# ATtiny26 device description
Architecture: AVR8; Family: tinyAVR
Registers are 8-bit, access not given, no defined reset value unless marked. A register's access mark holds for its fields unless they carry their own. Offsets are from the block's base; [hi:lo] are bit positions; 'fields as' and 'values as' point back to an identical list.

## PORTA — I/O Port
Instances: PORTA 0x00
0x39 PINA — Port A Input Pins
0x3A DDRA — Port A Data Direction Register
0x3B PORTA — Port A Data Register

## PORTB — I/O Port
Instances: PORTB 0x00
0x36 PINB — Port B Input Pins
0x37 DDRB — Port B Data Direction Register
0x38 PORTB — Port B Data Register

## EEPROM
Instances: EEPROM 0x00
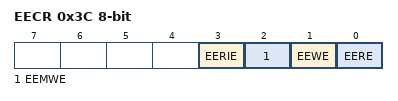
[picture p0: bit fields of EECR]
0x3C EECR — EEPROM Control Register
  [3] EERIE — EEProm Ready Interrupt Enable
  [2] EEMWE — EEPROM Master Write Enable
  [1] EEWE — EEPROM Write Enable
  [0] EERE — EEPROM Read Enable
0x3D EEDR — EEPROM Data Register
0x3E EEAR bits used 6:0 — EEPROM Read/Write Access

## WDT — Watchdog Timer
Instances: WDT 0x00
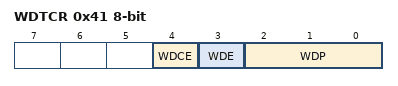
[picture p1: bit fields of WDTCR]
0x41 WDTCR — Watchdog Timer Control Register
  [4] WDCE — Watchdog Change Enable
  [3] WDE — Watch Dog Enable
  [2:0] WDP — Watch Dog Timer Prescaler bits
    0=Oscillator Cycles 16K; 1=Oscillator Cycles 32K; 2=Oscillator Cycles 64K; 3=Oscillator Cycles 128K; 4=Oscillator Cycles 256K; 5=Oscillator Cycles 512K; 6=Oscillator Cycles 1024K; 7=Oscillator Cycles 2048K

## CPU — CPU Registers
Instances: CPU 0x00
Parameters: CORE_VERSION=V1, NEW_INSTRUCTIONS=lpm rd,z
0x51 OSCCAL — Status Register
  [7:0] OSCCAL — Oscillator Calibration
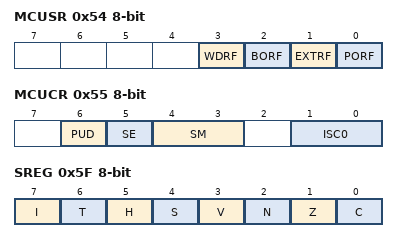
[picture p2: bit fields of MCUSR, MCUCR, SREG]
0x54 MCUSR — MCU Status register
  [3] WDRF — Watchdog Reset Flag
  [2] BORF — Brown-out Reset Flag
  [1] EXTRF — External Reset Flag
  [0] PORF — Power-On Reset Flag
0x55 MCUCR — MCU Control Register
  [6] PUD — Pull-up Disable
  [5] SE — Sleep Enable
  [4:3] SM — Sleep Mode Select Bits
    0=IDLE; 1=ADC (ADC Noise Reduction (If Available)); 2=PDOWN (Power Down); 3=STDBY (Standby)
  [1:0] ISC0 — Interrupt Sense Control 0 bits
    0=Low Level of INTX; 1=Any Logical Change in INTX; 2=Falling Edge of INTX; 3=Rising Edge of INTX
0x5D SP — Stack Pointer
0x5F SREG — Status Register
  [7] I — Global Interrupt Enable
  [6] T — Bit Copy Storage
  [5] H — Half Carry Flag
  [4] S — Sign Bit
  [3] V — Two's Complement Overflow Flag
  [2] N — Negative Flag
  [1] Z — Zero Flag
  [0] C — Carry Flag
Value list OSCCAL_VALUE_ADDRESSES: 0=1_0_MHz; 1=2_0_MHz; 2=4_0_MHz; 3=8_0_MHz

## TC0 (TC8 module) — Timer/Counter, 8-bit
Instances: TC0 0x00
0x52 TCNT0 — Timer Counter 0
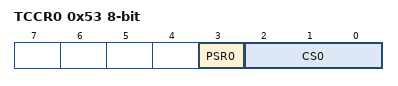
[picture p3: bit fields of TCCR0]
0x53 TCCR0 — Timer/Counter0 Control Register
  [3] PSR0 — Prescaler Reset Timer/Counter0
  [2:0] CS0 — Clock Select0 bits
    0=No Clock Source (Stopped); 1=Running, No Prescaling; 2=Running, CLK/8; 3=Running, CLK/64; 4=Running, CLK/256; 5=Running, CLK/1024; 6=Running, ExtClk Tx Falling Edge; 7=Running, ExtClk Tx Rising Edge
0x58 TIFR — Timer/Counter Interrupt Flag register
  [1] TOV0 — Timer/Counter0 Overflow Flag
0x59 TIMSK — Timer/Counter Interrupt Mask Register
  [1] TOIE0 — Timer/Counter0 Overflow Interrupt Enable

## TC1 (TC8 module) — Timer/Counter, 8-bit
Instances: TC1 0x00
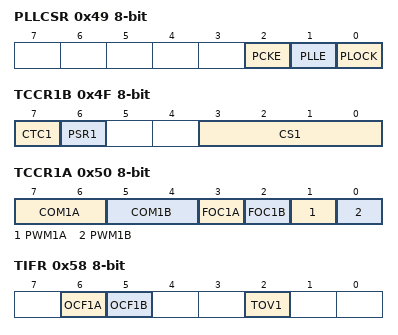
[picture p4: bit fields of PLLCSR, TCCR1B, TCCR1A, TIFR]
0x49 PLLCSR — PLL Control and Status Register
  [2] PCKE — PCK Enable
  [1] PLLE — PLL Enable
  [0] PLOCK — PLL Lock Detector
0x4B OCR1C — Output Compare Register
0x4C OCR1B — Output Compare Register
0x4D OCR1A — Output Compare Register
0x4E TCNT1 — Timer/Counter Register
0x4F TCCR1B — Timer/Counter Control Register B
  [7] CTC1 — Clear Timer/Counter on Compare Match
  [6] PSR1 — Prescaler Reset Timer/Counter1
  [3:0] CS1 — Clock Select Bits
    0=No Clock Source (Stopped); 1=Running, No Prescaling; 2=Running, CLK/2; 3=Running, CLK/4; 4=Running, CLK/8; 5=Running, CLK/16; 6=Running, CLK/32; 7=Running, CLK/64; 8=Running, CLK/128; 9=Running, CLK/256; 10=Running, CLK/512; 11=Running, CLK/1024; 12=Running, CLK/2048; 13=Running, CLK/4096; 14=Running, CLK/8192; 15=Running, CLK/16384
0x50 TCCR1A — Timer/Counter Control Register A
  [7:6] COM1A — Comparator A Output Mode Bits
    0=Disconnected from OCn/PWMn; 1=Toggle OCn/PWMn output line; 2=Clear OCn/PWMn output line; 3=set OCn/PWMn output line
  [5:4] COM1B — Comparator B Output Mode Bits
    values as COM1A
  [3] FOC1A — Force Output Compare Match 1A
  [2] FOC1B — Force Output Compare Match 1B
  [1] PWM1A — Pulse Width Modulator A Enable
  [0] PWM1B — Pulse Width Modulator B Enable
0x58 TIFR — Timer/Counter Interrupt Flag Register
  [6] OCF1A — Timer/Counter1 Output Compare Flag 1A
  [5] OCF1B — Timer/Counter1 Output Compare Flag 1B
  [2] TOV1 — Timer/Counter1 Overflow Flag
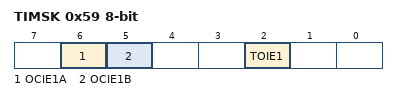
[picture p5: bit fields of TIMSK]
0x59 TIMSK — Timer/Counter Interrupt Mask Register
  [6] OCIE1A — Timer/Counter1 Output Compare Interrupt Enable
  [5] OCIE1B — Timer/Counter1 Output Compare Interrupt Enable
  [2] TOIE1 — Timer/Counter1 Overflow Interrupt Enable

## EXINT — External Interrupts
Instances: EXINT 0x00
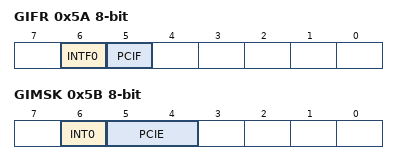
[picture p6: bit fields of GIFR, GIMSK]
0x5A GIFR — General Interrupt Flag register
  [6] INTF0 — External Interrupt Flag 0
  [5] PCIF — Pin Change Interrupt Flag
0x5B GIMSK — General Interrupt Mask Register
  [6] INT0 — External Interrupt Request 0 Enable
  [5:4] PCIE — Pin Change Interrupt Enables
